# PIC18F56Q84 register map
Vendor: Microchip
Registers are 8-bit, read-write, reset 0x0 unless marked. A register's access mark holds for its fields unless they carry their own. Addresses are absolute, and some are shared; only a register's first bit layout is shown; [hi:lo] are bit positions; {n}, {i} and the like mark numbered series.

## cla_clc
0xD5 CLCSELECT
  [2:0] SLCT
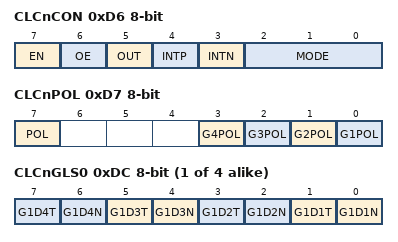
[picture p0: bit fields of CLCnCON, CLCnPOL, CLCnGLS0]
0xD6 CLCnCON — Configurable logic cell control
  [7] EN, [6] OE, [5] OUT ro, [4] INTP, [3] INTN, [2:0] MODE
0xD7 CLCnPOL reset not defined — Polarity control (power-on value 0---xxxx)
  [7] POL, [n-1] G{n}POL (n=1..4)
{0xD8+i} CLCnSEL{i} reset not defined (i=0..3) — Input select register 1 (power-on value xxxxxxxx)
  [7:0] D{i+1}S
{0xDC+i} CLCnGLS{i} reset not defined (i=0..3) — Gate logic select register {i} (power-on value xxxxxxxx)
  [2n-1] G{i+1}D{n}T (n=1..4), [2n-2] G{i+1}D{n}N (n=1..4)

## dma
0xE8 DMASELECT — DMA instance selection register
  [2:0] SLCT
0xE9 DMAnBUF ro reset not defined — DMA data buffer (power-on value xxxxxxxx)
  [7:0] BUF
0xEA DMAnDCNTL
  [7:0] DCNT
0xEB DMAnDCNTH
  [3:0] DCNT
0xEC DMAnDPTRL ro
  [7:0] DPTR
0xED DMAnDPTRH ro
  [7:0] DPTR
0xEE DMAnDSZL reset not defined — (power-on value xxxxxxxx)
  [7:0] DSZ
0xEF DMAnDSZH
  [3:0] DSZ
0xF0 DMAnDSAL reset not defined — (power-on value xxxxxxxx)
  [7:0] DSA
0xF1 DMAnDSAH
  [7:0] DSA
0xF2 DMAnSCNTL
  [7:0] SCNT
0xF3 DMAnSCNTH
  [3:0] SCNT
0xF4 DMAnSPTRL ro
  [7:0] SPTR
0xF5 DMAnSPTRH ro
  [7:0] SPTR
0xF6 DMAnSPTRU ro
  [5:0] SPTR
0xF7 DMAnSSZL
  [7:0] SSZ
0xF8 DMAnSSZH
  [3:0] SSZ
0xF9 DMAnSSAL
  [7:0] SSA
0xFA DMAnSSAH
  [7:0] SSA
0xFB DMAnSSAU
  [5:0] SSA
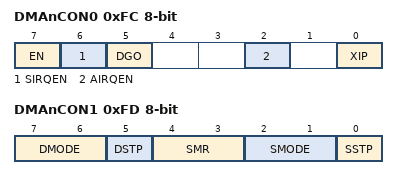
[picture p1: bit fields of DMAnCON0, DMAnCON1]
0xFC DMAnCON0 — DMA control register 0
  [7] EN, [6] SIRQEN, [5] DGO, [2] AIRQEN, [0] XIP ro
0xFD DMAnCON1 — DMA control register 1
  [7:6] DMODE, [5] DSTP, [4:3] SMR, [2:1] SMODE, [0] SSTP
0xFE DMAnAIRQ — DMA abort trigger selection register
  [7:0] AIRQ
0xFF DMAnSIRQ — DMA start trigger selection register
  [7:0] SIRQ

## DOS_xxxxx_pps_mid_v2_output_6xK40_8bit
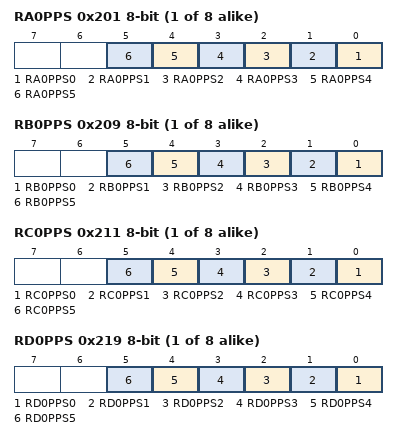
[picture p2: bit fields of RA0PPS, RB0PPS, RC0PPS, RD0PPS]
{0x201+i} RA{i}PPS (i=0..7)
  [n] RA{i}PPS{n} (n=0..5)
{0x209+i} RB{i}PPS (i=0..7)
  [n] RB{i}PPS{n} (n=0..5)
{0x211+i} RC{i}PPS (i=0..7)
  [n] RC{i}PPS{n} (n=0..5)
{0x219+i} RD{i}PPS (i=0..7)
  [n] RD{i}PPS{n} (n=0..5)
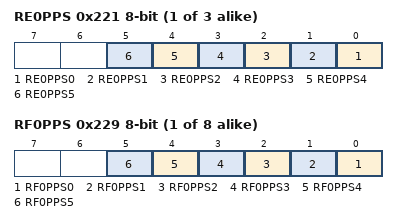
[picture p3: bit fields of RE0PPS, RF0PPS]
{0x221+i} RE{i}PPS (i=0..2)
  [n] RE{i}PPS{n} (n=0..5)
{0x229+i} RF{i}PPS (i=0..7)
  [n] RF{i}PPS{n} (n=0..5)

## DOS_xxxx_pps_mid
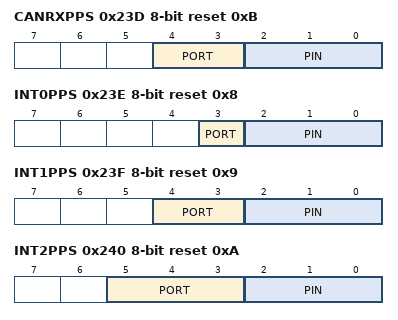
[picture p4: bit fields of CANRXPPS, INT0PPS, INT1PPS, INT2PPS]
0x23D CANRXPPS reset 0xB
  [4:3] PORT, [2:0] PIN
0x23E INT0PPS reset 0x8
  [3] PORT, [2:0] PIN
0x23F INT1PPS reset 0x9
  [4:3] PORT, [2:0] PIN
0x240 INT2PPS reset 0xA
  [5:3] PORT, [2:0] PIN
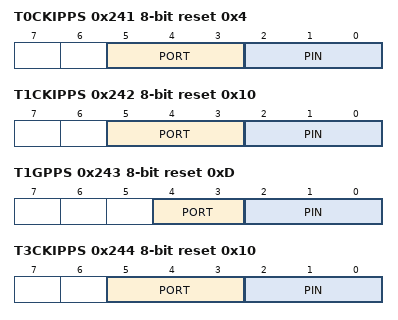
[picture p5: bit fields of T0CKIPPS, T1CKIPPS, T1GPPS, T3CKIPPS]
0x241 T0CKIPPS reset 0x4
  [5:3] PORT, [2:0] PIN
0x242 T1CKIPPS reset 0x10
  [5:3] PORT, [2:0] PIN
0x243 T1GPPS reset 0xD
  [4:3] PORT, [2:0] PIN
0x244 T3CKIPPS reset 0x10
  [5:3] PORT, [2:0] PIN
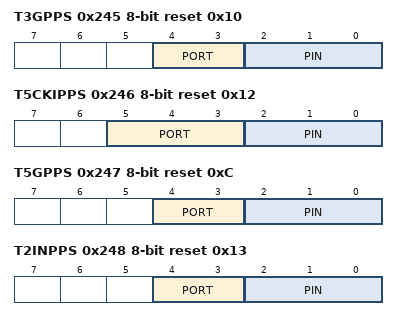
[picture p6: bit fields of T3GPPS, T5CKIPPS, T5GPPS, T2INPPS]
0x245 T3GPPS reset 0x10
  [4:3] PORT, [2:0] PIN
0x246 T5CKIPPS reset 0x12
  [5:3] PORT, [2:0] PIN
0x247 T5GPPS reset 0xC
  [4:3] PORT, [2:0] PIN
0x248 T2INPPS reset 0x13
  [4:3] PORT, [2:0] PIN
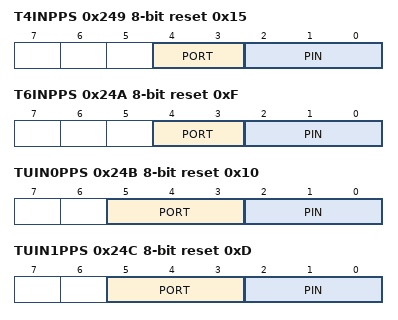
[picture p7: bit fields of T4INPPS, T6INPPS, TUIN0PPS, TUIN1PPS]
0x249 T4INPPS reset 0x15
  [4:3] PORT, [2:0] PIN
0x24A T6INPPS reset 0xF
  [4:3] PORT, [2:0] PIN
0x24B TUIN0PPS reset 0x10
  [5:3] PORT, [2:0] PIN
0x24C TUIN1PPS reset 0xD
  [5:3] PORT, [2:0] PIN
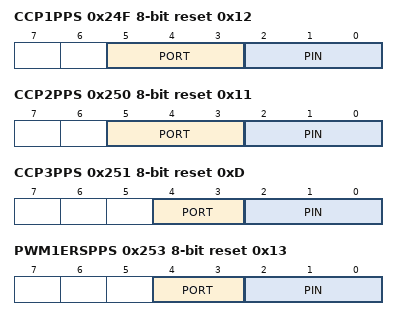
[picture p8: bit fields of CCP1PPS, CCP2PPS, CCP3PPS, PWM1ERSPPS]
0x24F CCP1PPS reset 0x12
  [5:3] PORT, [2:0] PIN
0x250 CCP2PPS reset 0x11
  [5:3] PORT, [2:0] PIN
0x251 CCP3PPS reset 0xD
  [4:3] PORT, [2:0] PIN
0x253 PWM1ERSPPS reset 0x13
  [4:3] PORT, [2:0] PIN
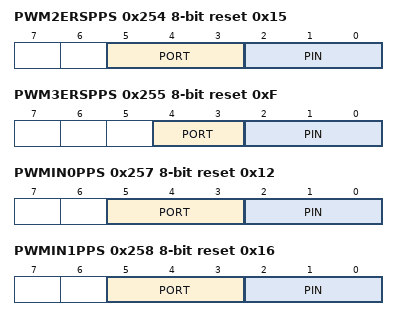
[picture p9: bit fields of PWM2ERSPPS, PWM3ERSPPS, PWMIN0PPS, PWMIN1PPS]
0x254 PWM2ERSPPS reset 0x15
  [5:3] PORT, [2:0] PIN
0x255 PWM3ERSPPS reset 0xF
  [4:3] PORT, [2:0] PIN
0x256 PWM4ERSPPS reset 0x13
0x257 PWMIN0PPS reset 0x12
  [5:3] PORT, [2:0] PIN
0x258 PWMIN1PPS reset 0x16
  [5:3] PORT, [2:0] PIN
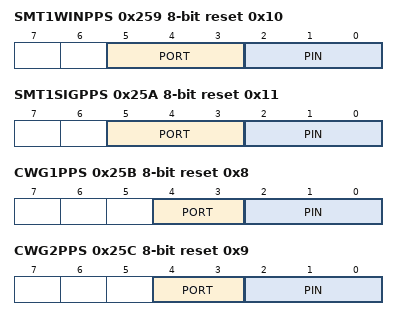
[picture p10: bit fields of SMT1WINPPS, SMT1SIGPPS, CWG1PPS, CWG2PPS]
0x259 SMT1WINPPS reset 0x10
  [5:3] PORT, [2:0] PIN
0x25A SMT1SIGPPS reset 0x11
  [5:3] PORT, [2:0] PIN
0x25B CWG1PPS reset 0x8
  [4:3] PORT, [2:0] PIN
0x25C CWG2PPS reset 0x9
  [4:3] PORT, [2:0] PIN
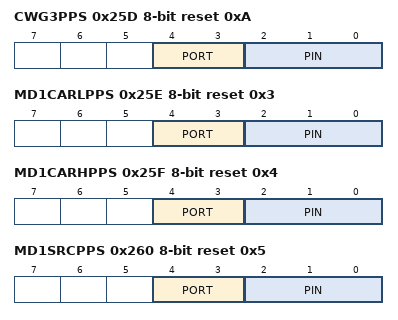
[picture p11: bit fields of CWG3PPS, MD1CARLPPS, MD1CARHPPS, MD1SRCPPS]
0x25D CWG3PPS reset 0xA
  [4:3] PORT, [2:0] PIN
0x25E MD1CARLPPS reset 0x3
  [4:3] PORT, [2:0] PIN
0x25F MD1CARHPPS reset 0x4
  [4:3] PORT, [2:0] PIN
0x260 MD1SRCPPS reset 0x5
  [4:3] PORT, [2:0] PIN
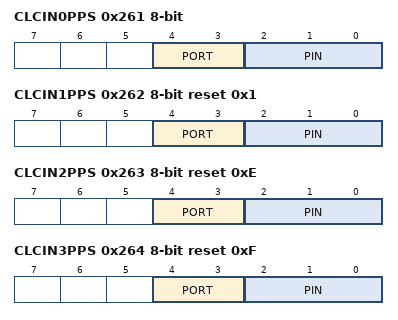
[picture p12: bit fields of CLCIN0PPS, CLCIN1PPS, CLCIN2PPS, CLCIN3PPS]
0x261 CLCIN0PPS
  [4:3] PORT, [2:0] PIN
0x262 CLCIN1PPS reset 0x1
  [4:3] PORT, [2:0] PIN
0x263 CLCIN2PPS reset 0xE
  [4:3] PORT, [2:0] PIN
0x264 CLCIN3PPS reset 0xF
  [4:3] PORT, [2:0] PIN
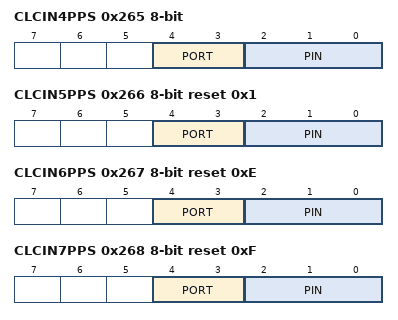
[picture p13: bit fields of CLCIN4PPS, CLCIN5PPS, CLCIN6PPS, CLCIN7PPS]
0x265 CLCIN4PPS
  [4:3] PORT, [2:0] PIN
0x266 CLCIN5PPS reset 0x1
  [4:3] PORT, [2:0] PIN
0x267 CLCIN6PPS reset 0xE
  [4:3] PORT, [2:0] PIN
0x268 CLCIN7PPS reset 0xF
  [4:3] PORT, [2:0] PIN
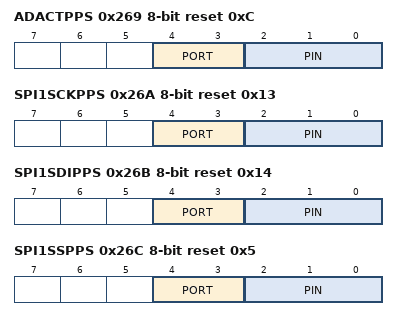
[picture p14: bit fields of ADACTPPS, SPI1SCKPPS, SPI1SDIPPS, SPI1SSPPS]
0x269 ADACTPPS reset 0xC
  [4:3] PORT, [2:0] PIN
0x26A SPI1SCKPPS reset 0x13
  [4:3] PORT, [2:0] PIN
0x26B SPI1SDIPPS reset 0x14
  [4:3] PORT, [2:0] PIN
0x26C SPI1SSPPS reset 0x5
  [4:3] PORT, [2:0] PIN
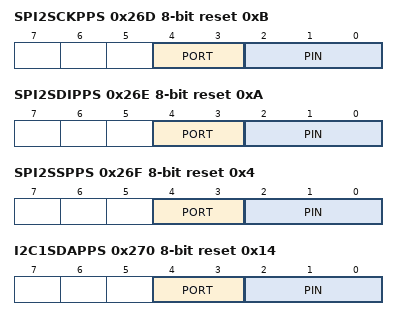
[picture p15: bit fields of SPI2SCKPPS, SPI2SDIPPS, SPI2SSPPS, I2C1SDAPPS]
0x26D SPI2SCKPPS reset 0xB
  [4:3] PORT, [2:0] PIN
0x26E SPI2SDIPPS reset 0xA
  [4:3] PORT, [2:0] PIN
0x26F SPI2SSPPS reset 0x4
  [4:3] PORT, [2:0] PIN
0x270 I2C1SDAPPS reset 0x14
  [4:3] PORT, [2:0] PIN
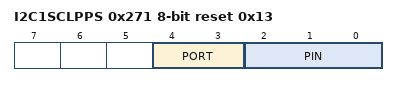
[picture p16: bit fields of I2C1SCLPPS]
0x271 I2C1SCLPPS reset 0x13
  [4:3] PORT, [2:0] PIN
0x272 U1RXPPS reset 0x17
  [5:3] PORT, [2:0] PIN
0x273 U1CTSPPS reset 0x16
  [5:3] PORT, [2:0] PIN
0x274 U2RXPPS reset 0xF
  [4:3] PORT, [2:0] PIN
0x275 U2CTSPPS reset 0xE
  [4:3] PORT, [2:0] PIN
0x276 U3RXPPS reset 0x7
  [5:3] PORT, [2:0] PIN
0x277 U3CTSPPS reset 0x6
  [5:3] PORT, [2:0] PIN
0x278 U4RXPPS reset 0xD
  [4:3] PORT, [2:0] PIN
0x279 U4CTSPPS reset 0xC
  [4:3] PORT, [2:0] PIN
0x27A U5RXPPS reset 0x5
  [5:3] PORT, [2:0] PIN
0x27B U5CTSPPS reset 0x4
  [5:3] PORT, [2:0] PIN
